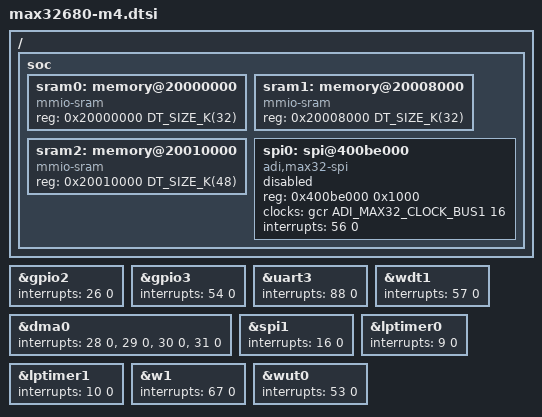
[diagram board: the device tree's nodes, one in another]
/*
 * Copyright (c) 2024-2026 Analog Devices, Inc.
 *
 * SPDX-License-Identifier: Apache-2.0
 */

#include <adi/max32/max32680.dtsi>
#include <adi/max32/max32xxx-m4.dtsi>

/ {
	soc {
		sram0: memory@20000000 {
			compatible = "mmio-sram";
			reg = <0x20000000 DT_SIZE_K(32)>;
		};

		sram1: memory@20008000 {
			compatible = "mmio-sram";
			reg = <0x20008000 DT_SIZE_K(32)>;
		};

		sram2: memory@20010000 {
			compatible = "mmio-sram";
			reg = <0x20010000 DT_SIZE_K(48)>;
		};

		spi0: spi@400be000 {
			compatible = "adi,max32-spi";
			reg = <0x400be000 0x1000>;
			#address-cells = <1>;
			#size-cells = <0>;
			clocks = <&gcr ADI_MAX32_CLOCK_BUS1 16>;
			interrupts = <56 0>;
			status = "disabled";
		};
	};
};

&gpio2 {
	interrupts = <26 0>;
};

&gpio3 {
	interrupts = <54 0>;
};

&uart3 {
	interrupts = <88 0>;
};

&dma0 {
	interrupts = <28 0>, <29 0>, <30 0>, <31 0>;
};

&wdt1 {
	interrupts = <57 0>;
};

&spi1 {
	interrupts = <16 0>;
};

&lptimer0 {
	interrupts = <9 0>;
};

&lptimer1 {
	interrupts = <10 0>;
};

&w1 {
	interrupts = <67 0>;
};

&wut0 {
	interrupts = <53 0>;
};
